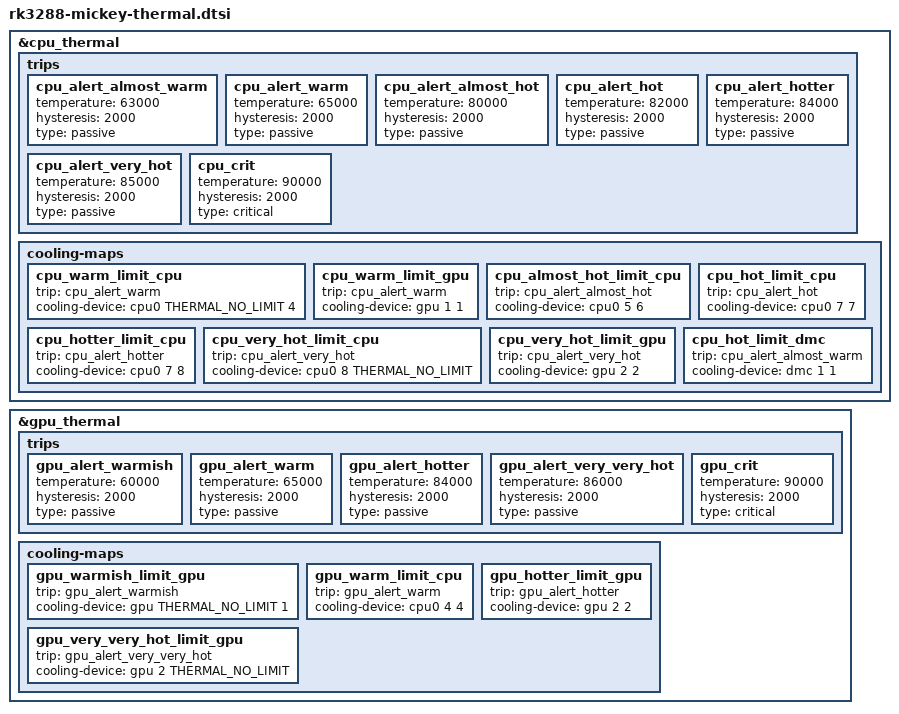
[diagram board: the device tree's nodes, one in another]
/*
 * Device Tree Source for RK3288 SoC thermal on mickey
 *
 * Copyright (c) 2014, Fuzhou Rockchip Electronics Co., Ltd
 *
 * This file is licensed under the terms of the GNU General Public License
 * version 2.  This program is licensed "as is" without any warranty of any
 * kind, whether express or implied.
 */

&cpu_thermal {
	/delete-node/ trips;
	/delete-node/ cooling-maps;

	trips {
		cpu_alert_almost_warm: cpu_alert_almost_warm {
			temperature = <63000>; /* millicelsius */
			hysteresis = <2000>; /* millicelsius */
			type = "passive";
		};
		cpu_alert_warm: cpu_alert_warm {
			temperature = <65000>; /* millicelsius */
			hysteresis = <2000>; /* millicelsius */
			type = "passive";
		};
		cpu_alert_almost_hot: cpu_alert_almost_hot {
			temperature = <80000>; /* millicelsius */
			hysteresis = <2000>; /* millicelsius */
			type = "passive";
		};
		cpu_alert_hot: cpu_alert_hot {
			temperature = <82000>; /* millicelsius */
			hysteresis = <2000>; /* millicelsius */
			type = "passive";
		};
		cpu_alert_hotter: cpu_alert_hotter {
			temperature = <84000>; /* millicelsius */
			hysteresis = <2000>; /* millicelsius */
			type = "passive";
		};
		cpu_alert_very_hot: cpu_alert_very_hot {
			temperature = <85000>; /* millicelsius */
			hysteresis = <2000>; /* millicelsius */
			type = "passive";
		};
		cpu_crit: cpu_crit {
			temperature = <90000>; /* millicelsius */
			hysteresis = <2000>; /* millicelsius */
			type = "critical";
		};
	};

	cooling-maps {
		/*
		 * After 1st level, throttle the CPU down to as low as 1.4 GHz
		 * and don't let the GPU go faster than 400 MHz.  Note that we
		 * won't throttle the GPU lower than 400 MHz due to CPU
		 * heat--we'll let the GPU do the rest itself.
		 */
		cpu_warm_limit_cpu {
			trip = <&cpu_alert_warm>;
			cooling-device =
				<&cpu0 THERMAL_NO_LIMIT 4>;
		};
		cpu_warm_limit_gpu {
			trip = <&cpu_alert_warm>;
			cooling-device =
				<&gpu 1 1>;
		};

		/*
		 * Add some discrete steps to help throttling system deal
		 * with the fact that there are two passive cooling devices:
		 * the CPU and the GPU.
		 *
		 * - 1.2 GHz - 1.0 GHz (almost hot)
		 * - 800 MHz           (hot)
		 * - 800 MHz - 696 MHz (hotter)
		 * - 696 MHz - min     (very hot)
		 *
		 * Note:
		 * - 800 MHz appears to be a "sweet spot" for me.  I can run
		 *   some pretty serious workload here and be happy.
		 * - After 696 MHz we stop lowering voltage, so throttling
		 *   past there is less effective.
		 */
		cpu_almost_hot_limit_cpu {
			trip = <&cpu_alert_almost_hot>;
			cooling-device =
				<&cpu0 5 6>;
		};
		cpu_hot_limit_cpu {
			trip = <&cpu_alert_hot>;
			cooling-device =
				<&cpu0 7 7>;
		};
		cpu_hotter_limit_cpu {
			trip = <&cpu_alert_hotter>;
			cooling-device =
				<&cpu0 7 8>;
		};
		cpu_very_hot_limit_cpu {
			trip = <&cpu_alert_very_hot>;
			cooling-device =
				<&cpu0 8 THERMAL_NO_LIMIT>;
		};

		/* At very hot, don't let GPU go over 300 MHz */
		cpu_very_hot_limit_gpu {
			trip = <&cpu_alert_very_hot>;
			cooling-device =
				<&gpu 2 2>;
		};

		/*
		 * When a little warm we'll drop down to 433MHz memory.  This
		 * is enough for a reasonable amount of work and since
		 * everything in mickey is so tightly packed together we'll
		 * totally cap it to 433 until we cool down enough (we won't
		 * allow speeding up if the trend is falling).
		 *
		 * For now we won't go down to 333MHz since the thermal
		 * framework doesn't properly implement hysteresis and
		 * pingponging between 433 and 333 near the high end of the
		 * temperature range affects speed a lot.
		 *
		 * We lock into certain frequencies instead of allowing the
		 * thermal framework to work with a range for a few reasons:
		 * 1. The thermal framework has lots of ways to cool down the
		 *    cpu.  It has no way to known how to trade off between CPU
		 *    and memory, so this helps keep it from trying to do both
		 *    at the same time.
		 * 2. Flipping DMC frequencies is expensive.  If we did it as
		 *    much as the thermal framework wanted we'd just waste good
		 *    processing time.
		 * 3. Once we're really hot it's hard to flip DMC frequencies
		 *    because the CPU isn't running fast enough to complete the
		 *    needed work in time.
		 *
		 * Note that we always flip DMC freq a little before CPU freq.
		 * Again, this is to avoid lots of expensive flipping.
		 */
		cpu_hot_limit_dmc {
			trip = <&cpu_alert_almost_warm>;
			cooling-device =
				<&dmc 1 1>;
		};
	};
};

&gpu_thermal {
	/delete-node/ trips;
	/delete-node/ cooling-maps;

	trips {
		gpu_alert_warmish: gpu_alert_warmish {
			temperature = <60000>; /* millicelsius */
			hysteresis = <2000>; /* millicelsius */
			type = "passive";
		};
		gpu_alert_warm: gpu_alert_warm {
			temperature = <65000>; /* millicelsius */
			hysteresis = <2000>; /* millicelsius */
			type = "passive";
		};
		gpu_alert_hotter: gpu_alert_hotter {
			temperature = <84000>; /* millicelsius */
			hysteresis = <2000>; /* millicelsius */
			type = "passive";
		};
		gpu_alert_very_very_hot: gpu_alert_very_very_hot {
			temperature = <86000>; /* millicelsius */
			hysteresis = <2000>; /* millicelsius */
			type = "passive";
		};
		gpu_crit: gpu_crit {
			temperature = <90000>; /* millicelsius */
			hysteresis = <2000>; /* millicelsius */
			type = "critical";
		};
	};

	cooling-maps {
		/* After 1st level throttle the GPU down to as low as 400 MHz */
		gpu_warmish_limit_gpu {
			trip = <&gpu_alert_warmish>;
			cooling-device =
				<&gpu THERMAL_NO_LIMIT 1>;
		};

		/*
		 * Slightly after we throttle the GPU, we'll also make sure that
		 * the CPU can't go faster than 1.4 GHz.  Note that we won't
		 * throttle the CPU lower than 1.4 GHz due to GPU heat--we'll
		 * let the CPU do the rest itself.
		 */
		gpu_warm_limit_cpu {
			trip = <&gpu_alert_warm>;
			cooling-device =
				<&cpu0 4 4>;
		};

		/* When hot, GPU goes down to 300 MHz */
		gpu_hotter_limit_gpu {
			trip = <&gpu_alert_hotter>;
			cooling-device =
				<&gpu 2 2>;
		};

		/* When really hot, don't let GPU go _above_ 300 MHz */
		gpu_very_very_hot_limit_gpu {
			trip = <&gpu_alert_very_very_hot>;
			cooling-device =
				<&gpu 2 THERMAL_NO_LIMIT>;
		};
	};
};
